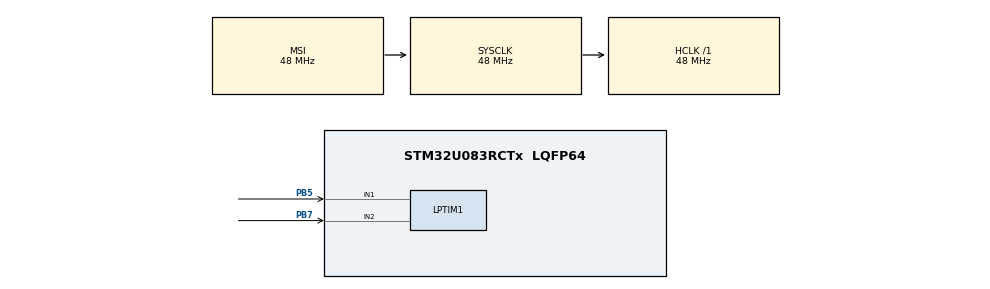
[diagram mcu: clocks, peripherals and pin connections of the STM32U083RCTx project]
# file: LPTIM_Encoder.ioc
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LPTIM1.TriggerSource=LPTIM_TRIGSOURCE_SOFTWARE
LPTIM1.ULPClockPolarity=LPTIM_CLOCKPOLARITY_RISING
LPTIM1.ULPClockSampleTime=LPTIM_CLOCKSAMPLETIME_DIRECTTRANSITION
LPTIM1.UpdateMode=LPTIM_UPDATE_IMMEDIATE
Mcu.Family=STM32U0
Mcu.Name=STM32U083RCTx
Mcu.Package=LQFP64
NVIC.PriorityGroup=NVIC_PRIORITYGROUP_2
NVIC.TIM6_DAC_LPTIM1_IRQn=true\:0\:0\:false\:false\:true\:true\:true\:true
PB5.GPIO_Speed=GPIO_SPEED_FREQ_VERY_HIGH
PB5.Mode=Encoder_mode_occur1
PB5.Signal=LPTIM1_IN1
PB7.GPIO_Speed=GPIO_SPEED_FREQ_VERY_HIGH
PB7.Mode=Encoder_mode_occur1
PB7.Signal=LPTIM1_IN2
ProjectManager.HeapSize=0x200
ProjectManager.StackSize=0x400
ProjectManager.TargetToolchain=EWARM V9.20
RCC.ADCFreq_Value=48000000
RCC.AHBFreq_Value=48000000
RCC.CortexFreq_Value=48000000
RCC.HCLKFreq_Value=48000000
RCC.HSE_VALUE=4000000
RCC.HSI48_VALUE=48000000
RCC.HSI_VALUE=16000000
RCC.LSE_VALUE=32768
RCC.MSIClockRangeVal=RCC_MSIRANGE_11
RCC.MSI_VALUE=48000000
RCC.PLLM=RCC_PLLM_DIV8
RCC.PLLN=8
RCC.PLLSourceVirtual=RCC_PLLSOURCE_MSI
RCC.SYSCLKFreq_VALUE=48000000
RCC.SYSCLKSource=RCC_SYSCLKSOURCE_MSI
RCC.USBFreq_Value=48000000
RCC.VCOOutputFreq_Value=48000000
VP_PWR_VS_SECSignals.Mode=Security/Privilege
board=custom

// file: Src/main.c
/* USER CODE BEGIN Header */
/**
  ******************************************************************************
  * @file    LPTIM/LPTIM_Encoder/Src/main.c
  * @author  MCD Application Team
  * @brief   This sample code shows how to use STM32U0xx TIM HAL API to generate
  *          a time base of one second with the corresponding Interrupt request.
  ******************************************************************************
  * @attention
  *
  * Copyright (c) 2023 STMicroelectronics.
  * All rights reserved.
  *
  * This software is licensed under terms that can be found in the LICENSE file
  * in the root directory of this software component.
  * If no LICENSE file comes with this software, it is provided AS-IS.
  *
  ******************************************************************************
  */
/* USER CODE END Header */
#include "main.h"

LPTIM_HandleTypeDef hlptim1;

void SystemClock_Config(void);
static void MX_GPIO_Init(void);
static void MX_LPTIM1_Init(void);

int main(void)
{
  /* USER CODE BEGIN 1 */
/* STM32U0xx HAL library initialization:
       - Configure the Flash prefetch
       - Systick timer is configured by default as source of time base, but user
         can eventually implement his proper time base source (a general purpose
         timer for example or other time source), keeping in mind that Time base
         duration should be kept 1ms since PPP_TIMEOUT_VALUEs are defined and
         handled in milliseconds basis.
       - Low Level Initialization
     */
  /* USER CODE END 1 */

  /* MCU Configuration--------------------------------------------------------*/

  /* Reset of all peripherals, Initializes the Flash interface and the Systick. */
  HAL_Init();

  /* Configure the system clock */
  SystemClock_Config();

  /* USER CODE BEGIN SysInit */
  BSP_LED_Init(LED4);

  /* USER CODE END SysInit */

  /* Initialize all configured peripherals */
  MX_GPIO_Init();
  MX_LPTIM1_Init();
  /* USER CODE BEGIN 2 */
   if (HAL_OK != HAL_LPTIM_Encoder_Start(&hlptim1))
  {
    Error_Handler();
  }

  /* USER CODE END 2 */

  /* Infinite loop */
  while (1)
  {

    /* USER CODE BEGIN 3 */
    /* GPIO Toggling to generate a square signals with different phases  */
    HAL_GPIO_TogglePin(GPIOB, GPIO_PIN_3);
    /* Insert delay 1 ms */
    HAL_Delay(10);
    HAL_GPIO_TogglePin(GPIOB, GPIO_PIN_4);

    /* Up counting : set phase of signal 1 to 0 and phase of signal 2 to 270 */
    if (__HAL_LPTIM_GET_FLAG(&hlptim1,LPTIM_FLAG_UP))
    {
      /* Turn LED4 off  */
      BSP_LED_On(LED4);
      __HAL_LPTIM_CLEAR_FLAG(&hlptim1,LPTIM_FLAG_UP);
      HAL_Delay(10);

     }
    else
    {
      /* Down counting : set phase of signal 1 to 0 and phase of signal 2 to 90 */
      if (__HAL_LPTIM_GET_FLAG(&hlptim1,LPTIM_FLAG_DOWN))
      {
        /* Turn LED4 on  */
        BSP_LED_Off(LED4);
        __HAL_LPTIM_CLEAR_FLAG(&hlptim1,LPTIM_FLAG_DOWN);
        HAL_Delay(10);
      }
     }
     HAL_Delay(10);
  }
  /* USER CODE END 3 */
}

void SystemClock_Config(void)
{
  RCC_OscInitTypeDef RCC_OscInitStruct = {0};
  RCC_ClkInitTypeDef RCC_ClkInitStruct = {0};

  /** Configure the main internal regulator output voltage
  */
  HAL_PWREx_ControlVoltageScaling(PWR_REGULATOR_VOLTAGE_SCALE1);

  /** Initializes the RCC Oscillators according to the specified parameters
  * in the RCC_OscInitTypeDef structure.
  */
  RCC_OscInitStruct.OscillatorType = RCC_OSCILLATORTYPE_MSI;
  RCC_OscInitStruct.MSIState = RCC_MSI_ON;
  RCC_OscInitStruct.MSICalibrationValue = RCC_MSICALIBRATION_DEFAULT;
  RCC_OscInitStruct.MSIClockRange = RCC_MSIRANGE_11;
  RCC_OscInitStruct.PLL.PLLState = RCC_PLL_NONE;
  if (HAL_RCC_OscConfig(&RCC_OscInitStruct) != HAL_OK)
  {
    Error_Handler();
  }

  /** Initializes the CPU, AHB and APB buses clocks
  */
  RCC_ClkInitStruct.ClockType = RCC_CLOCKTYPE_HCLK|RCC_CLOCKTYPE_SYSCLK
                              |RCC_CLOCKTYPE_PCLK1;
  RCC_ClkInitStruct.SYSCLKSource = RCC_SYSCLKSOURCE_MSI;
  RCC_ClkInitStruct.AHBCLKDivider = RCC_SYSCLK_DIV1;
  RCC_ClkInitStruct.APB1CLKDivider = RCC_HCLK_DIV1;

  if (HAL_RCC_ClockConfig(&RCC_ClkInitStruct, FLASH_LATENCY_1) != HAL_OK)
  {
    Error_Handler();
  }
}

static void MX_LPTIM1_Init(void)
{

  hlptim1.Instance = LPTIM1;
  hlptim1.Init.Clock.Source = LPTIM_CLOCKSOURCE_APBCLOCK_LPOSC;
  hlptim1.Init.Clock.Prescaler = LPTIM_PRESCALER_DIV1;
  hlptim1.Init.UltraLowPowerClock.Polarity = LPTIM_CLOCKPOLARITY_RISING;
  hlptim1.Init.UltraLowPowerClock.SampleTime = LPTIM_CLOCKSAMPLETIME_DIRECTTRANSITION;
  hlptim1.Init.Trigger.Source = LPTIM_TRIGSOURCE_SOFTWARE;
  hlptim1.Init.Period = 65535;
  hlptim1.Init.UpdateMode = LPTIM_UPDATE_IMMEDIATE;
  hlptim1.Init.CounterSource = LPTIM_COUNTERSOURCE_EXTERNAL;
  hlptim1.Init.Input1Source = LPTIM_INPUT1SOURCE_GPIO;
  hlptim1.Init.Input2Source = LPTIM_INPUT2SOURCE_GPIO;
  hlptim1.Init.RepetitionCounter = 0;
  if (HAL_LPTIM_Init(&hlptim1) != HAL_OK)
  {
    Error_Handler();
  }

}

static void MX_GPIO_Init(void)
{

  /* GPIO Ports Clock Enable */
  __HAL_RCC_GPIOB_CLK_ENABLE();

}

void Error_Handler(void)
{
  /* USER CODE BEGIN Error_Handler_Debug */
  /* User can add his own implementation to report the HAL error return state */

  while (1)
  {
 /* LED4 toggles each 1s */
  BSP_LED_Toggle(LED4);
  HAL_Delay(1000);
  }
  /* USER CODE END Error_Handler_Debug */
}
